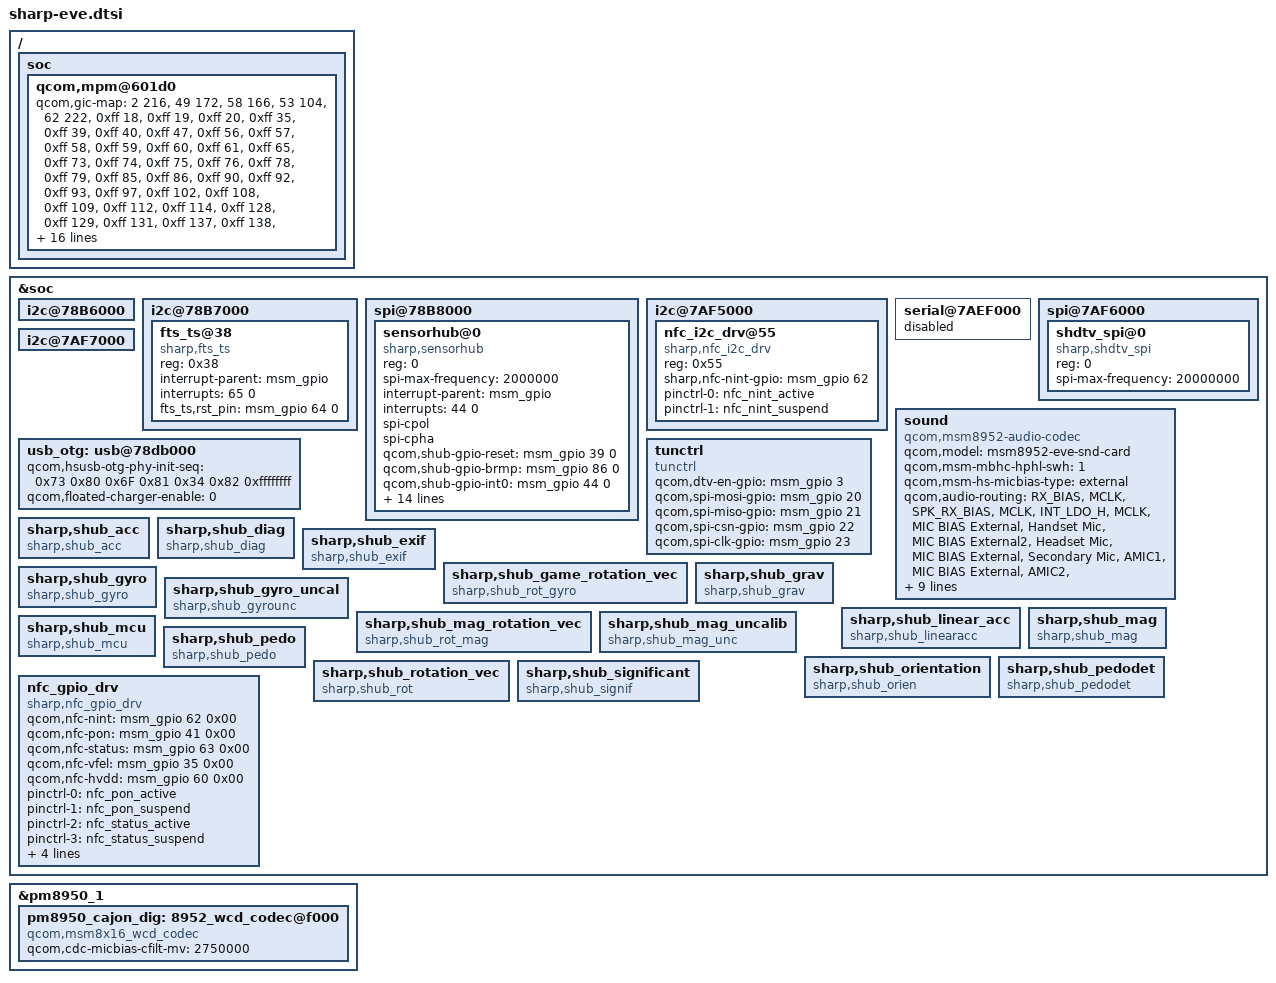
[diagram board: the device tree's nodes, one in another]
/* 
 * Copyright (c) 2016, Sharp Inc. All rights reserved.
 * Copyright (c) 2015, The Linux Foundation. All rights reserved.
 *
 * This program is free software; you can redistribute it and/or modify
 * it under the terms of the GNU General Public License version 2 and
 * only version 2 as published by the Free Software Foundation.
 *
 * This program is distributed in the hope that it will be useful,
 * but WITHOUT ANY WARRANTY; without even the implied warranty of
 * MERCHANTABILITY or FITNESS FOR A PARTICULAR PURPOSE.  See the
 * GNU General Public License for more details.
 */

#include "sharp_pinctrl/sharp-pinctrl-eve.dtsi"
#include "sharp-eve-display.dtsi"

/ {
	soc {
		/delete-node/ qcom,msm-ssc-sensors;

		qcom,mpm@601d0 {
			qcom,gic-map = <2 216>, /* tsens_upper_lower_int */
				<49 172>, /* usb1_hs_async_wakeup_irq */
				<58 166>, /* usb_hs_irq */
				<53 104>, /* mdss_irq */
				<62 222>, /* ee0_krait_hlos_spmi_periph_irq */
				<0xff 18>,  /* APC_qgicQTmrSecPhysIrptReq */
				<0xff 19>,  /* APC_qgicQTmrNonSecPhysIrptReq */
				<0xff 20>,  /* qgicQTmrVirtIrptReq */
				<0xff 35>,  /* WDT_barkInt */
				<0xff 39>,  /* arch_mem_timer */
				<0xff 40>,  /* qtmr_phy_irq[0] */
				<0xff 47>,  /* rbif_irq[0] */
				<0xff 56>,  /* q6_wdog_expired_irq */
				<0xff 57>,  /* mss_to_apps_irq(0) */
				<0xff 58>,  /* mss_to_apps_irq(1) */
				<0xff 59>,  /* mss_to_apps_irq(2) */
				<0xff 60>,  /* mss_to_apps_irq(3) */
				<0xff 61>,  /* mss_a2_bam_irq */
				<0xff 65>,  /* o_gc_sys_irq[0] */
				<0xff 73>,  /* smmu_intr_bus[1] */
				<0xff 74>,  /* smmu_bus_intr[2] */
				<0xff 75>,  /* smmu_bus_intr[3] */
				<0xff 76>,  /* venus_irq */
				<0xff 78>,  /* smmu_bus_intr[5] */
				<0xff 79>,  /* smmu_bus_intr[6] */
				<0xff 85>,  /* smmu_bus_intr[31] */
				<0xff 86>,  /* smmu_bus_intr[32] */
				<0xff 90>,  /* smmu_bus_intr[33] */
				<0xff 92>,  /* smmu_bus_intr[34] */
				<0xff 93>,  /* smmu_bus_intr[35] */
				<0xff 97>,  /* smmu_bus_intr[10] */
				<0xff 102>, /* smmu_bus_intr[14] */
				<0xff 108>, /* smmu_bus_intr[36] */
				<0xff 109>, /* smmu_bus_intr[37] */
				<0xff 112>, /* smmu_bus_intr[38] */
				<0xff 114>, /* qdsd_intr_out */
				<0xff 128>, /* blsp1_peripheral_irq[3] */
				<0xff 129>, /* blsp1_peripheral_irq[4] */
				<0xff 131>, /* qup_irq */
				<0xff 137>, /* smmu_intr_bus[44] */
				<0xff 138>, /* smmu_intr_bus[45] */
				<0xff 140>, /* uart_dm_intr */
				<0xff 142>, /* smmu_bus_intr[47] */
				<0xff 143>, /* smmu_bus_intr[48] */
				<0xff 144>, /* smmu_bus_intr[49] */
				<0xff 145>, /* smmu_bus_intr[50] */
				<0xff 146>, /* smmu_bus_intr[51] */
				<0xff 147>, /* smmu_bus_intr[52] */
				<0xff 148>, /* smmu_bus_intr[53] */
				<0xff 149>, /* smmu_bus_intr[54] */
				<0xff 150>, /* smmu_bus_intr[55] */
				<0xff 151>, /* smmu_bus_intr[56] */
				<0xff 152>, /* smmu_bus_intr[57] */
				<0xff 153>, /* smmu_bus_intr[58] */
				<0xff 155>, /* sdc1_irq(0) */
				<0xff 157>, /* sdc2_irq(0) */
				<0xff 167>, /* usb1_hs_bam_irq */
				<0xff 170>, /* sdc1_pwr_cmd_irq */
				<0xff 173>, /* o_wcss_apss_smd_hi */
				<0xff 174>, /* o_wcss_apss_smd_med */
				<0xff 175>, /* o_wcss_apss_smd_low */
				<0xff 176>, /* o_wcss_apss_smsm_irq */
				<0xff 177>, /* o_wcss_apss_wlan_data_xfer_done */
				<0xff 178>, /* o_wcss_apss_wlan_rx_data_avail */
				<0xff 179>, /* o_wcss_apss_asic_intr */
				<0xff 181>, /* o_wcss_apss_wdog_bite_and_reset_rdy */
				<0xff 188>, /* lpass_irq_out_apcs(0) */
				<0xff 189>, /* lpass_irq_out_apcs(1) */
				<0xff 190>, /* lpass_irq_out_apcs(2) */
				<0xff 191>, /* lpass_irq_out_apcs(3) */
				<0xff 192>, /* lpass_irq_out_apcs(4) */
				<0xff 193>, /* lpass_irq_out_apcs(5) */
				<0xff 194>, /* lpass_irq_out_apcs(6) */
				<0xff 195>, /* lpass_irq_out_apcs(7) */
				<0xff 196>, /* lpass_irq_out_apcs(8) */
				<0xff 197>, /* lpass_irq_out_apcs(9) */
				<0xff 198>, /* coresight-tmc-etr interrupt */
				<0xff 200>, /* rpm_ipc(4) */
				<0xff 201>, /* rpm_ipc(5) */
				<0xff 202>, /* rpm_ipc(6) */
				<0xff 203>, /* rpm_ipc(7) */
				<0xff 204>, /* rpm_ipc(24) */
				<0xff 205>, /* rpm_ipc(25) */
				<0xff 206>, /* rpm_ipc(26) */
				<0xff 207>, /* rpm_ipc(27) */
				<0xff 215>, /* o_bimc_intr[0] */
				<0xff 224>, /* SPDM interrupt */
				<0xff 239>, /* crypto_bam_irq[1]*/
				<0xff 240>, /* summary_irq_kpss */
				<0xff 253>, /* sdc2_pwr_cmd_irq */
				<0xff 260>, /* ipa_irq[0] */
				<0xff 262>, /* ipa_bam_irq[2] */
				<0xff 269>, /* rpm_wdog_expired_irq */
				<0xff 270>, /* blsp1_bam_irq[0] */
				<0xff 271>, /* blsp2_bam_irq[0] */
				<0xff 272>, /* smmu_intr_bus[17] */
				<0xff 273>, /* smmu_bus_intr[18] */
				<0xff 274>, /* smmu_bus_intr[19] */
				<0xff 275>, /* rpm_ipc(30) */
				<0xff 276>, /* rpm_ipc(31) */
				<0xff 277>, /* smmu_intr_bus[20] */
				<0xff 321>, /* q6ss_irq_out(4) */
				<0xff 322>, /* q6ss_irq_out(5) */
				<0xff 323>, /* q6ss_irq_out(6) */
				<0xff 325>; /* q6ss_wdog_exp_irq */
		};

	};
};

&soc {
	/*****************************************/
	/*  BLSP#1                               */
	/*****************************************/

	/*****************************************/
	/*  BLSP#2(BLSP1_QUP2)                   */
	/*****************************************/
	i2c@78B6000 {
		status = "ok";
	};

	/*****************************************/
	/*  BLSP#3(BLSP1_QUP3)                   */
	/*****************************************/
	i2c@78B7000 {
		status = "ok";
		fts_ts@38 {
			status = "ok";
			compatible = "sharp,fts_ts";
			reg = <0x38>;
			interrupt-parent = <&msm_gpio>;
			interrupts = <65 0>;

			/* user defined property */
			fts_ts,rst_pin = <&msm_gpio 64 0>;
		};
	};

	/*****************************************/
	/*  BLSP#4(BLSP1_QUP4)                   */
	/*****************************************/
	spi@78B8000 {
		status = "ok";
		sensorhub@0 {
			status = "ok";
			compatible = "sharp,sensorhub";
			reg = <0>;
			spi-max-frequency = <2000000>;
			interrupt-parent = <&msm_gpio>;
			interrupts = <44 0>;
			spi-cpol;
			spi-cpha;
			qcom,shub-gpio-reset = <&msm_gpio 39 0>;
			qcom,shub-gpio-brmp = <&msm_gpio 86 0>;
			qcom,shub-gpio-int0 = <&msm_gpio 44 0>;
			qcom,shub-gpio-int1 = <&msm_gpio 42 0>;
			pinctrl-names = "shub_reset_active","shub_reset_suspend",
							"shub_int0_active","shub_int0_suspend",
							"shub_int0_pullup","shub_int0_pulldown",
							"shub_int1_active","shub_int1_suspend",
							"shub_brmp_active","shub_brmp_suspend";
			pinctrl-0 = <&shub_reset_active>;
			pinctrl-1 = <&shub_reset_suspend>;
			pinctrl-2 = <&shub_int0_active>;
			pinctrl-3 = <&shub_int0_suspend>;
			pinctrl-4 = <&shub_int0_pullup>;
			pinctrl-5 = <&shub_int0_pulldown>;
			pinctrl-6 = <&shub_int1_active>;
			pinctrl-7 = <&shub_int1_suspend>;
			pinctrl-8 = <&shub_brmp_active>;
			pinctrl-9 = <&shub_brmp_suspend>;
			shub,shub_acc_axis_val = <1>;
			shub,shub_gyro_axis_val = <1>;
			shub,shub_mag_axis_val = <1>;
		};
	};

	/*****************************************/
	/*  BLSP#5(BLSP2_QUP1)                   */
	/*****************************************/
	i2c@7AF5000 {
		status = "ok";

		nfc_i2c_drv@55 {
			status = "ok";
			compatible = "sharp,nfc_i2c_drv";
			reg = <0x55>;
			sharp,nfc-nint-gpio = <&msm_gpio 62 0x00>;
			pinctrl-names = "nfc_nint_active","nfc_nint_suspend";
			pinctrl-0 = <&nfc_nint_active>;
			pinctrl-1 = <&nfc_nint_suspend>;
		};
	};

	/*****************************************/
	/*  BLSP#5(BLSP2_LSUART1)                */
	/*****************************************/
	serial@7AEF000 {
		status = "disabled";
	};

	/*****************************************/
	/*  BLSP#6(BLSP2_QUP2)                   */
	/*****************************************/
	spi@7AF6000 {
		status = "ok";

		shdtv_spi@0 {
			status = "ok";
			compatible = "sharp,shdtv_spi";
			reg = <0>;
			spi-max-frequency = <20000000>;
/*			spi-cpol; */
/*			spi-cpha; */
		};
	};

	/*****************************************/
	/*  BLSP#7(BLSP2_QUP3)                   */
	/*****************************************/
	i2c@7AF7000 {
		status = "ok";
	};

	/*****************************************/
	/*  BLSP#8                               */
	/*****************************************/
	sound {
		compatible = "qcom,msm8952-audio-codec";
		qcom,model = "msm8952-eve-snd-card";
		qcom,msm-mbhc-hphl-swh = <1>;
		qcom,msm-hs-micbias-type = "external";
		qcom,audio-routing =
			"RX_BIAS", "MCLK",
			"SPK_RX_BIAS", "MCLK",
			"INT_LDO_H", "MCLK",
			"MIC BIAS External", "Handset Mic",
			"MIC BIAS External2", "Headset Mic",
			"MIC BIAS External", "Secondary Mic",
			"AMIC1", "MIC BIAS External",
			"AMIC2", "MIC BIAS External2",
			"AMIC3", "MIC BIAS External";
		qcom,msm-gpios =
			"pri_i2s";
		qcom,pinctrl-names =
			"all_off",
			"pri_i2s_act";
		pinctrl-names =
			"all_off",
			"pri_i2s_act";
		/delete-property/ qcom,msm-micbias1-ext-cap;
		/delete-property/ qcom,cdc-us-euro-gpios;
		pinctrl-0 = <&cdc_pdm_lines_sus &cdc_pdm_lines_2_sus>;
		pinctrl-1 = <&cdc_pdm_lines_act &cdc_pdm_lines_2_act>;
		/delete-property/ pinctrl-2;
		/delete-property/ pinctrl-3;
		/delete-property/ asoc-wsa-codec-names;
		sharp,jack-lineout-report = "notsend";
		sharp,jack-detect-port = "gnd";
	};

	usb_otg: usb@78db000 {
		qcom,hsusb-otg-phy-init-seq =
			<0x73 0x80 0x6F 0x81 0x34 0x82 0xffffffff>;
		qcom,floated-charger-enable = <0>;
	};

	tunctrl {
		compatible = "tunctrl";
		qcom,dtv-en-gpio = <&msm_gpio 3 0x00>;
		qcom,spi-mosi-gpio = <&msm_gpio 20 0x00>;
		qcom,spi-miso-gpio = <&msm_gpio 21 0x00>;
		qcom,spi-csn-gpio = <&msm_gpio 22 0x00>;
		qcom,spi-clk-gpio = <&msm_gpio 23 0x00>;
	};

    sharp,shub_acc {
	     status = "ok";
	     compatible = "sharp,shub_acc";
	};

    sharp,shub_diag {
	     status = "ok";
	     compatible = "sharp,shub_diag";
	};

    sharp,shub_exif {
	     status = "ok";
	     compatible = "sharp,shub_exif";
	};

    sharp,shub_game_rotation_vec {
	     status = "ok";
	     compatible = "sharp,shub_rot_gyro";
	};

    sharp,shub_grav {
	     status = "ok";
	     compatible = "sharp,shub_grav";
	};

    sharp,shub_gyro {
	     status = "ok";
	     compatible = "sharp,shub_gyro";
	};

    sharp,shub_gyro_uncal {
	     status = "ok";
	     compatible = "sharp,shub_gyrounc";
	};

    sharp,shub_linear_acc {
	     status = "ok";
	     compatible = "sharp,shub_linearacc";
	};

    sharp,shub_mag {
	     status = "ok";
	     compatible = "sharp,shub_mag";
	};

    sharp,shub_mag_rotation_vec {
	     status = "ok";
	     compatible = "sharp,shub_rot_mag";
	};

    sharp,shub_mag_uncalib {
	     status = "ok";
	     compatible = "sharp,shub_mag_unc";
	};

    sharp,shub_mcu {
	     status = "ok";
	     compatible = "sharp,shub_mcu";
	};

    sharp,shub_orientation {
	     status = "ok";
	     compatible = "sharp,shub_orien";
	};

    sharp,shub_pedo {
	     status = "ok";
	     compatible = "sharp,shub_pedo";
	};

    sharp,shub_pedodet {
	     status = "ok";
	     compatible = "sharp,shub_pedodet";
	};

    sharp,shub_rotation_vec {
	     status = "ok";
	     compatible = "sharp,shub_rot";
	};

    sharp,shub_significant {
	     status = "ok";
	     compatible = "sharp,shub_signif";
	};

	nfc_gpio_drv {
		compatible = "sharp,nfc_gpio_drv";
		qcom,nfc-nint   = <&msm_gpio 62 0x00>;
		qcom,nfc-pon    = <&msm_gpio 41 0x00>;
		qcom,nfc-status = <&msm_gpio 63 0x00>;
		qcom,nfc-vfel   = <&msm_gpio 35 0x00>;
		qcom,nfc-hvdd   = <&msm_gpio 60 0x00>;
		pinctrl-names = "nfc_pon_active","nfc_pon_suspend",
						"nfc_status_active","nfc_status_suspend",
						"nfc_vfel_active","nfc_vfel_suspend",
						"nfc_hvdd_active","nfc_hvdd_suspend";
		pinctrl-0 = <&nfc_pon_active>;
		pinctrl-1 = <&nfc_pon_suspend>;
		pinctrl-2 = <&nfc_status_active>;
		pinctrl-3 = <&nfc_status_suspend>;
		pinctrl-4 = <&nfc_vfel_active>;
		pinctrl-5 = <&nfc_vfel_suspend>;
		pinctrl-6 = <&nfc_hvdd_active>;
		pinctrl-7 = <&nfc_hvdd_suspend>;
	};

};
&pm8950_1 {
	pm8950_cajon_dig: 8952_wcd_codec@f000 {
		compatible = "qcom,msm8x16_wcd_codec";
		qcom,cdc-micbias-cfilt-mv = <2750000>;
	};
};
#include "sharp-eve-vib.dtsi"
#include "sharp-eve-pm8952.dtsi"
#include "sharp-eve-pmi8952.dtsi"
